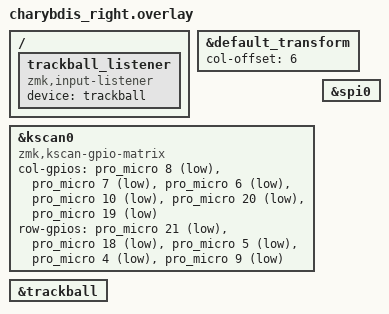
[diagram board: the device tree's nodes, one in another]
#include "charybdis.dtsi"
#include "charybdis_pmw3610.dtsi"

// The matrix transform is 6 columns over because the left half is 6 columns wide.
&default_transform {
	col-offset = <6>;
};

&kscan0 {
	compatible = "zmk,kscan-gpio-matrix";
	
	col-gpios
		= <&pro_micro 8 GPIO_ACTIVE_LOW>
		, <&pro_micro 7 GPIO_ACTIVE_LOW>
		, <&pro_micro 6 GPIO_ACTIVE_LOW>
		, <&pro_micro 10 GPIO_ACTIVE_LOW>
		, <&pro_micro 20 GPIO_ACTIVE_LOW>
		, <&pro_micro 19 GPIO_ACTIVE_LOW>
		;

	row-gpios
                = <&pro_micro 21 (GPIO_ACTIVE_LOW | GPIO_PULL_UP)>
                , <&pro_micro 18 (GPIO_ACTIVE_LOW | GPIO_PULL_UP)>
                , <&pro_micro 5  (GPIO_ACTIVE_LOW | GPIO_PULL_UP)>
                , <&pro_micro 4  (GPIO_ACTIVE_LOW | GPIO_PULL_UP)>
                , <&pro_micro 9  (GPIO_ACTIVE_LOW | GPIO_PULL_UP)>
                ;
};

&spi0 {
    status = "okay";
};

&trackball {
    status = "okay";
};

// https://github.com/badjeff/zmk-pmw3610-driver
/ {
  trackball_listener {
    compatible = "zmk,input-listener";
    device = <&trackball>;
  };
};
